VERSION ""

NS_ :

BS_:

BU_: Vector__XXX VEHICLE HMI FLUX_CAPACITOR TIME_CIRCUITS RADAR_DEVICE

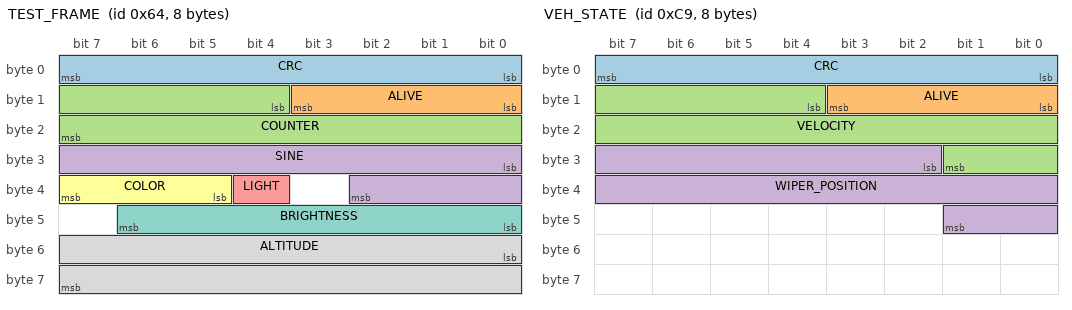
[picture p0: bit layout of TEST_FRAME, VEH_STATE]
BO_ 100 TEST_FRAME: 8 VEHICLE
  SG_ CRC : 0|8@1+ (1,0) [0|255] "" Vector__XXX
  SG_ ALIVE : 8|4@1+ (1,0) [0|15] "" Vector__XXX
  SG_ COUNTER : 12|12@1+ (1,0) [0|4095] "" Vector__XXX
  SG_ SINE : 24|11@1+ (0.001,-1.0) [-1.0|1.0] "" Vector__XXX
  SG_ LIGHT : 36|1@1+ (1,0) [0|1] "" Vector__XXX
  SG_ COLOR : 37|3@1+ (1,0) [0|15] "" Vector__XXX
  SG_ BRIGHTNESS : 40|7@1+ (1,0) [0|100] "%" Vector__XXX
  SG_ ALTITUDE : 48|16@1+ (0.001,0) [0|65535] "km" Vector__XXX

BO_ 201 VEH_STATE: 8 VEHICLE
  SG_ CRC : 0|8@1+ (1,0) [0|255] "" Vector__XXX
  SG_ ALIVE : 8|4@1+ (1,0) [0|15] "" Vector__XXX
  SG_ VELOCITY : 12|14@1+ (0.01,0) [0|140] "mph" Vector__XXX
  SG_ WIPER_POSITION : 26|16@1+ (0.010986328125,0) [0|180] "deg" Vector__XXX

BO_ 233 FLUX: 6 FLUX_CAPACITOR
  SG_ POWER_LEVEL : 0|32@1+ (0.000000001,0) [0|4.0] "GW" Vector__XXX
  SG_ DISPERSAL_RATE : 32|13@1+ (0.01220703125,0) [0|100] "%" Vector__XXX

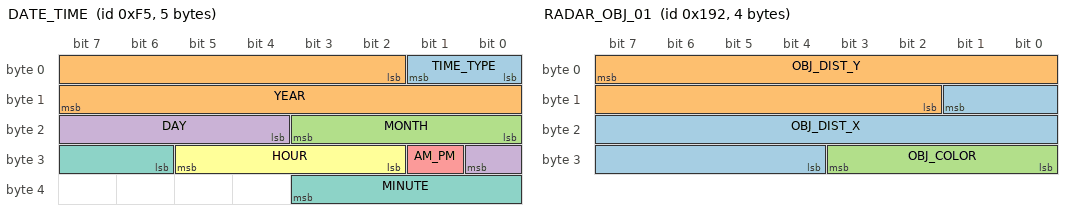
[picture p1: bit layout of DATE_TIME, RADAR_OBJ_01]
BO_ 245 DATE_TIME: 5 TIME_CIRCUITS
  SG_ TIME_TYPE : 0|2@1+ (1,0) [0|3] "" VEHICLE,FLUX_CAPACITOR
  SG_ YEAR : 2|14@1+ (1,0) [0|9999] "" VEHICLE,FLUX_CAPACITOR
  SG_ MONTH : 16|4@1+ (1,0) [1|12] "" VEHICLE,FLUX_CAPACITOR
  SG_ DAY : 20|5@1+ (1,0) [1|31] "" VEHICLE,FLUX_CAPACITOR
  SG_ AM_PM : 25|1@1+ (1,0) [0|1] "" VEHICLE,FLUX_CAPACITOR
  SG_ HOUR : 26|4@1+ (1,0) [0|12] "" VEHICLE,FLUX_CAPACITOR
  SG_ MINUTE : 30|6@1+ (1,0) [0|60] "" VEHICLE,FLUX_CAPACITOR

BO_ 402 RADAR_OBJ_01: 4 RADAR_DEVICE
  SG_ OBJ_DIST_X : 9|14@0+ (0.01,0) [0|150] "m" Vector__XXX
  SG_ OBJ_DIST_Y : 7|14@0+ (0.01,0) [0|150] "m" Vector__XXX
  SG_ OBJ_COLOR : 27|4@0+ (1,0) [0|0] "" Vector__XXX

BO_ 502 FUEL: 5 VEHICLE
  SG_ FUEL_TYPE M : 0|1@1+ (1,0) [0|0] "" HMI
  SG_ RESERVED : 1|7@1+ (1,0) [0|0] "" HMI
  SG_ E_RANGE m0 : 8|8@1+ (1,0) [0|250] "km" HMI
  SG_ GAS_RANGE m1 : 8|10@1+ (1,0) [0|1000] "km" HMI
  SG_ E_CONS m0 : 16|10@1+ (100,0) [0|100] "Wh/100km" HMI
  SG_ GAS_CONS m1 : 18|10@1+ (0.1,0) [0|100] "l/100km" HMI
  SG_ BAT_VOLT m0 : 26|12@1+ (0.1,0) [0|400] "V" HMI
  SG_ CHARGING m0 : 38|1@1+ (1,0) [0|0] "" HMI
  SG_ SUPER_CHARGING m0 : 39|1@1+ (1,0) [0|0] "" HMI

VAL_ 100 LIGHT 0 "OFF" 1 "ON" ;
VAL_ 100 COLOR 0 "UNDEFINED" 1 "RED" 2 "ORANGE" 3 "BLUE" 4 "YELLOW" 5 "GREEN" 6 "VIOLET" 7 "FUCHSIA" ;
